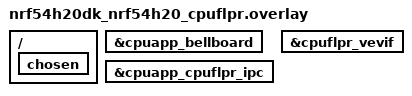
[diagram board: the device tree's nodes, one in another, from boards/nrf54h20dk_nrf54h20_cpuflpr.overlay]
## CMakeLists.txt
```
#
# Copyright (c) 2025 Nordic Semiconductor ASA
#
# SPDX-License-Identifier: LicenseRef-Nordic-5-Clause
#

cmake_minimum_required(VERSION 3.20.0)

find_package(Zephyr REQUIRED HINTS $ENV{ZEPHYR_BASE})
project(remote_cpurad)

# target_include_directories(app PRIVATE ${CMAKE_CURRENT_SOURCE_DIR}/../common)

zephyr_library_include_directories(
    src
    ../common
)

# Define which device this is
zephyr_compile_definitions(ZBUS_DEVICE_B=1)

target_sources(app PRIVATE src/main.c)
```

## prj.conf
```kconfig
# Copyright (c) 2025 Nordic Semiconductor ASA
# SPDX-License-Identifier: LicenseRef-Nordic-5-Clause

CONFIG_LOG=y
# CONFIG_LOG_MODE_MINIMAL=y
CONFIG_LOG_DBG_COLOR_BLUE=y

# Boot without banners
CONFIG_BOOT_BANNER=y

CONFIG_MBOX=y
CONFIG_IPC_SERVICE=y
CONFIG_HEAP_MEM_POOL_SIZE=4096

CONFIG_TEST_RANDOM_GENERATOR=y

CONFIG_ZBUS=y

CONFIG_ZBUS_MULTIDOMAIN=y
CONFIG_ZBUS_MULTIDOMAIN_IPC=y
CONFIG_ZBUS_MULTIDOMAIN_LOG_LEVEL_DBG=n

# Increase the size of the receive buffer to accommodate larger messages
CONFIG_PBUF_RX_READ_BUF_SIZE=384
```

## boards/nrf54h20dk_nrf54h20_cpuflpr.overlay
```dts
&cpuapp_bellboard {
	status = "okay";
};

ipc0: &cpuapp_cpuflpr_ipc {
	status = "okay";
};

&cpuflpr_vevif {
	status = "okay";
};

/ {
	chosen {
		/delete-property/ zephyr,bt-hci;
	};
};
```

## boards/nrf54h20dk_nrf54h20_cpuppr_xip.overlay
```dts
&cpuapp_bellboard {
	status = "okay";
};

ipc0: &cpuapp_cpuppr_ipc {
	status = "okay";
};

&cpuppr_vevif {
	status = "okay";
};

/ {
	chosen {
		/delete-property/ zephyr,bt-hci;
	};
};
```

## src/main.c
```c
#include <zephyr/kernel.h>
#include <zephyr/logging/log.h>
#include <zephyr/random/random.h>
#include <string.h>
#include <zephyr/zbus/zbus.h>
#include <zephyr/zbus/multidomain/zbus_multidomain.h>

#include "common.h"

LOG_MODULE_REGISTER(main, LOG_LEVEL_DBG);

/* NOTE: Shared channels request_channel and response_channel are defined in common.h */

/* Set up proxy agent for ipc0 and add response channel to be forwarded */
ZBUS_PROXY_AGENT_DEFINE(ipc_proxy, ZBUS_MULTIDOMAIN_TYPE_IPC, ipc0);
ZBUS_PROXY_ADD_CHANNEL(ipc_proxy, response_channel);

int get_random_value(int min, int max)
{
    return min + (sys_rand32_get() % (max - min + 1));
}

/* Listen for requests on the request channel, and respond on the response channel */
static void ipc_forwarder_listener_cb(const struct zbus_channel *chan)
{
    LOG_INF("Received message on channel %s", chan->name);
    const struct request_data *data = zbus_chan_const_msg(chan);
    LOG_INF("Request ID: %d, Min: %d, Max: %d", data->request_id, data->min_value, data->max_value);

    /* Simulate a response */
    struct response_data response = {
        .response_id = data->request_id,
        .value = get_random_value(data->min_value, data->max_value)
    };

    LOG_INF("Sending response: ID=%d, Value=%d", response.response_id, response.value);

    int ret = zbus_chan_pub(&response_channel, &response, K_MSEC(100));
    if (ret < 0) {
        LOG_ERR("Failed to publish response on channel %s: %d", response_channel.name, ret);
    } else {
        LOG_INF("Response published on channel %s", response_channel.name);
    }
}
ZBUS_LISTENER_DEFINE(ipc_forwarder_listener, ipc_forwarder_listener_cb);
ZBUS_CHAN_ADD_OBS(request_channel, ipc_forwarder_listener, 0);

bool print_channel_info(const struct zbus_channel *chan)
{
    if (chan == NULL) {
        LOG_ERR("Channel is NULL");
        return false;
    }
    LOG_INF("Channel %s is a %s channel",
            chan->name,
            ZBUS_CHANNEL_IS_SHADOW(chan) ? "shadow" : "master");
    return true;
}

int main(void)
{
    LOG_INF("ZBUS Multidomain IPC Forwarder Sample Application");
    zbus_iterate_over_channels(print_channel_info);

    return 0;
}
```
